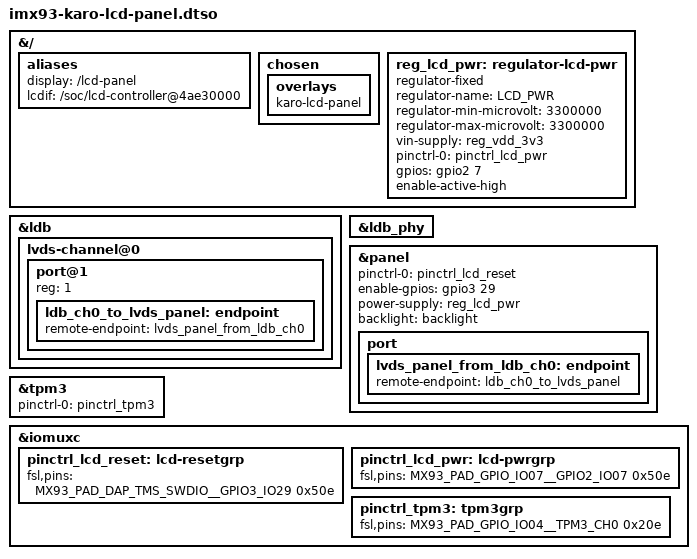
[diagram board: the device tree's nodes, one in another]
// SPDX-License-Identifier: (GPL-2.0 OR MIT)
/*
 * Copyright 2023 Lothar Waßmann <LW@KARO-electronics.de>
 *
 */

/dts-v1/;
/plugin/;

#include <dt-bindings/gpio/gpio.h>
#include <dt-bindings/pwm/pwm.h>
#include "includes/imx93-karo-backlight.dtsi"
#include "imx93-pinfunc.h"

&{/} {
	aliases {
		display = "/lcd-panel";
		lcdif = "/soc/lcd-controller@4ae30000";
	};

	chosen {
		overlays {
			karo-lcd-panel;
		};
	};

	reg_lcd_pwr: regulator-lcd-pwr {
		compatible = "regulator-fixed";
		regulator-name = "LCD_PWR";
		regulator-min-microvolt = <3300000>;
		regulator-max-microvolt = <3300000>;
		vin-supply = <&reg_vdd_3v3>;
		pinctrl-names = "default";
		pinctrl-0 = <&pinctrl_lcd_pwr>;
		gpios = <&gpio2 7 GPIO_ACTIVE_HIGH>;
		enable-active-high;
	};
};

&ldb {
	status = "okay";

	lvds-channel@0 {
		status = "okay";

		port@1 {
			reg = <1>;

			ldb_ch0_to_lvds_panel: endpoint {
				remote-endpoint = <&lvds_panel_from_ldb_ch0>;
			};
		};
	};
};

&ldb_phy {
	status = "okay";
};

&panel {
	pinctrl-names = "default";
	pinctrl-0 = <&pinctrl_lcd_reset>;
	enable-gpios = <&gpio3 29 GPIO_ACTIVE_HIGH>;
	power-supply = <&reg_lcd_pwr>;
	backlight = <&backlight>;

	port {
		lvds_panel_from_ldb_ch0: endpoint {
			remote-endpoint = <&ldb_ch0_to_lvds_panel>;
		};
	};
};

&tpm3 {
	pinctrl-names = "default";
	pinctrl-0 = <&pinctrl_tpm3>;
};

&iomuxc {
	pinctrl_lcd_reset: lcd-resetgrp {
		fsl,pins = <
			MX93_PAD_DAP_TMS_SWDIO__GPIO3_IO29	0x50e
		>;
	};

	pinctrl_lcd_pwr: lcd-pwrgrp {
		fsl,pins = <
			MX93_PAD_GPIO_IO07__GPIO2_IO07		0x50e
		>;
	};

	pinctrl_tpm3: tpm3grp {
		fsl,pins = <
			MX93_PAD_GPIO_IO04__TPM3_CH0		0x20e
		>;
	};
};
